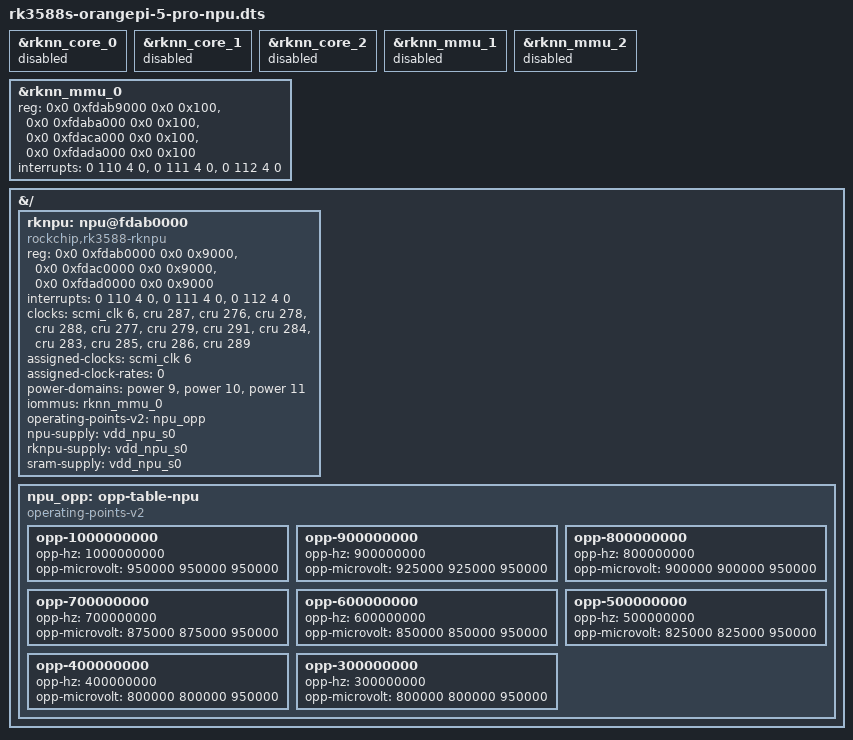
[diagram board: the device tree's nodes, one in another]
// SPDX-License-Identifier: GPL-2.0-only
// Generated by tools/overlays.sh from userpatches/.../dt/rk3588s-orangepi-5-pro-npu.dtsi.
/dts-v1/;
/plugin/;
&rknn_core_0 { status = "disabled"; };
&rknn_core_1 { status = "disabled"; };
&rknn_core_2 { status = "disabled"; };
&rknn_mmu_1 { status = "disabled"; };
&rknn_mmu_2 { status = "disabled"; };
&rknn_mmu_0 {
 reg = <0x0 0xfdab9000 0x0 0x100>,
   <0x0 0xfdaba000 0x0 0x100>,
   <0x0 0xfdaca000 0x0 0x100>,
   <0x0 0xfdada000 0x0 0x100>;
 interrupts = <0 110 4 0>,
   <0 111 4 0>,
   <0 112 4 0>;
};
&{/} {
 rknpu: npu@fdab0000 {
  compatible = "rockchip,rk3588-rknpu", "rockchip,rknpu";
  reg = <0x0 0xfdab0000 0x0 0x9000>,
       <0x0 0xfdac0000 0x0 0x9000>,
       <0x0 0xfdad0000 0x0 0x9000>;
  reg-names = "rknpu_core0", "rknpu_core1", "rknpu_core2";
  interrupts = <0 110 4 0>,
       <0 111 4 0>,
       <0 112 4 0>;
  interrupt-names = "npu0_irq", "npu1_irq", "npu2_irq";
  clocks = <&scmi_clk 6>,
   <&cru 287>, <&cru 276>, <&cru 278>,
   <&cru 288>, <&cru 277>, <&cru 279>,
   <&cru 291>, <&cru 284>,
   <&cru 283>, <&cru 285>,
   <&cru 286>, <&cru 289>;
  clock-names = "clk_npu", "aclk0", "aclk1", "aclk2",
        "hclk0", "hclk1", "hclk2",
        "pclk", "pclk_grf", "pclk_pvtm", "clk_pvtm",
        "clk_core_pvtm", "hclk_root";
  assigned-clocks = <&scmi_clk 6>;
  assigned-clock-rates = <0>;
  power-domains = <&power 9>,
      <&power 10>,
      <&power 11>;
  power-domain-names = "npu0", "npu1", "npu2";
  iommus = <&rknn_mmu_0>;
  operating-points-v2 = <&npu_opp>;
  npu-supply = <&vdd_npu_s0>;
  rknpu-supply = <&vdd_npu_s0>;
  sram-supply = <&vdd_npu_s0>;
  status = "okay";
 };
 npu_opp: opp-table-npu {
  compatible = "operating-points-v2";
  opp-1000000000 { opp-hz = /bits/ 64 <1000000000>; opp-microvolt = <950000 950000 950000>; };
  opp-900000000 { opp-hz = /bits/ 64 <900000000>; opp-microvolt = <925000 925000 950000>; };
  opp-800000000 { opp-hz = /bits/ 64 <800000000>; opp-microvolt = <900000 900000 950000>; };
  opp-700000000 { opp-hz = /bits/ 64 <700000000>; opp-microvolt = <875000 875000 950000>; };
  opp-600000000 { opp-hz = /bits/ 64 <600000000>; opp-microvolt = <850000 850000 950000>; };
  opp-500000000 { opp-hz = /bits/ 64 <500000000>; opp-microvolt = <825000 825000 950000>; };
  opp-400000000 { opp-hz = /bits/ 64 <400000000>; opp-microvolt = <800000 800000 950000>; };
  opp-300000000 { opp-hz = /bits/ 64 <300000000>; opp-microvolt = <800000 800000 950000>; };
 };
};
